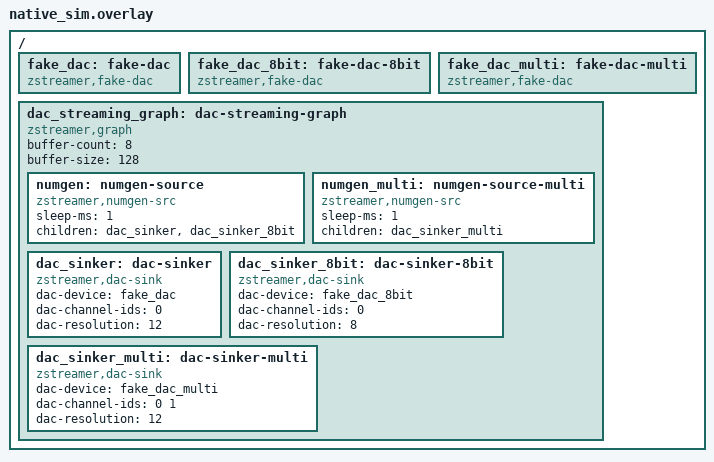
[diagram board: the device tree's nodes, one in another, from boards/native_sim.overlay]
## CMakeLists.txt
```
# Copyright (c) 2026 sharonthecreator
# SPDX-License-Identifier: Apache-2.0

cmake_minimum_required(VERSION 3.20.0)

# Pick up test-local DTS bindings (fake DAC).
list(APPEND DTS_ROOT ${CMAKE_CURRENT_SOURCE_DIR})

find_package(Zephyr REQUIRED HINTS $ENV{ZEPHYR_BASE})
project(zstreamer_dac_test)

target_sources(app PRIVATE
  src/main.c
  src/fake_dac.c
)
target_include_directories(app PRIVATE ${CMAKE_CURRENT_SOURCE_DIR}/../../include)
```

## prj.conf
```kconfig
# Copyright (c) 2026 sharonthecreator
# SPDX-License-Identifier: Apache-2.0

CONFIG_ZTEST=y
CONFIG_ZSTREAMER=y

# Sink under test
CONFIG_ZSTREAMER_DAC_SINK=y
CONFIG_DAC=y

# Test drivers
CONFIG_ZSTREAMER_TEST_NUMGEN_SRC=y

CONFIG_LOG=y
CONFIG_NET_BUF_POOL_USAGE=y
```

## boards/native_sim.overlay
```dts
/*
 * Copyright (c) 2026 sharonthecreator
 * SPDX-License-Identifier: Apache-2.0
 */

/ {
	fake_dac: fake-dac {
		compatible = "zstreamer,fake-dac";
		status = "okay";
	};

	fake_dac_8bit: fake-dac-8bit {
		compatible = "zstreamer,fake-dac";
		status = "okay";
	};

	fake_dac_multi: fake-dac-multi {
		compatible = "zstreamer,fake-dac";
		status = "okay";
	};

	dac_streaming_graph: dac-streaming-graph {
		compatible = "zstreamer,graph";
		buffer-count = <8>;
		buffer-size = <128>;

		numgen: numgen-source {
			compatible = "zstreamer,numgen-src";
			sleep-ms = <1>;
			children = <&dac_sinker>, <&dac_sinker_8bit>;
		};

		numgen_multi: numgen-source-multi {
			compatible = "zstreamer,numgen-src";
			sleep-ms = <1>;
			children = <&dac_sinker_multi>;
		};

		/* 12-bit sink, single channel */
		dac_sinker: dac-sinker {
			compatible = "zstreamer,dac-sink";
			dac-device = <&fake_dac>;
			dac-channel-ids = <0>;
			dac-resolution = <12>;
		};

		/* 8-bit sink, single channel */
		dac_sinker_8bit: dac-sinker-8bit {
			compatible = "zstreamer,dac-sink";
			dac-device = <&fake_dac_8bit>;
			dac-channel-ids = <0>;
			dac-resolution = <8>;
		};

		/* 12-bit sink, two channels (stereo) */
		dac_sinker_multi: dac-sinker-multi {
			compatible = "zstreamer,dac-sink";
			dac-device = <&fake_dac_multi>;
			dac-channel-ids = <0 1>;
			dac-resolution = <12>;
		};
	};
};
```

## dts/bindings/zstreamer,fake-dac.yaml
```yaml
# Copyright (c) 2026 sharonthecreator
# SPDX-License-Identifier: Apache-2.0

description: Fake DAC for testing the dac_sink driver.

compatible: "zstreamer,fake-dac"
```

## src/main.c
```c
/*
 * Copyright (c) 2026 sharonthecreator
 * SPDX-License-Identifier: Apache-2.0
 *
 * DAC sink zstreamer node driver tests.
 *
 * Pipeline: numgen-src → dac-sinker (12-bit) + dac-sinker-8bit (8-bit)
 * Both sinks receive every buffer from numgen; each writes to its own
 * fake DAC so recordings don't interleave.
 *
 * Multi-channel pipeline: numgen-multi → dac-sinker-multi (2ch, 12-bit)
 */

#include <string.h>

#include <zephyr/device.h>
#include <zephyr/net_buf.h>
#include <zephyr/ztest.h>

#include <zstreamer/node.h>
#include <zstreamer/source.h>
#include <zstreamer_test/helpers.h>

#include "fake_dac.h"

/* ------------------------------------------------------------------ */
/* DTS nodes                                                           */
/* ------------------------------------------------------------------ */

#define GRAPH_NODE          DT_NODELABEL(dac_streaming_graph)
#define NUMGEN_NODE         DT_NODELABEL(numgen)
#define NUMGEN_MULTI_NODE   DT_NODELABEL(numgen_multi)
#define DAC_SINK_NODE       DT_NODELABEL(dac_sinker)
#define DAC_SINK_8BIT_NODE  DT_NODELABEL(dac_sinker_8bit)
#define DAC_SINK_MULTI_NODE DT_NODELABEL(dac_sinker_multi)
#define FAKE_DAC_NODE       DT_NODELABEL(fake_dac)
#define FAKE_DAC_8BIT_NODE  DT_NODELABEL(fake_dac_8bit)
#define FAKE_DAC_MULTI_NODE DT_NODELABEL(fake_dac_multi)

static const struct device *graph_dev = DEVICE_DT_GET(GRAPH_NODE);
static const struct device *numgen_dev = DEVICE_DT_GET(NUMGEN_NODE);
static const struct device *numgen_multi_dev = DEVICE_DT_GET(NUMGEN_MULTI_NODE);
static const struct device *dac_sink_dev = DEVICE_DT_GET(DAC_SINK_NODE);
static const struct device *dac_sink_8bit_dev = DEVICE_DT_GET(DAC_SINK_8BIT_NODE);
static const struct device *dac_sink_multi_dev = DEVICE_DT_GET(DAC_SINK_MULTI_NODE);
static const struct device *fake_dac_dev = DEVICE_DT_GET(FAKE_DAC_NODE);
static const struct device *fake_dac_8bit_dev = DEVICE_DT_GET(FAKE_DAC_8BIT_NODE);
static const struct device *fake_dac_multi_dev = DEVICE_DT_GET(FAKE_DAC_MULTI_NODE);

/* ------------------------------------------------------------------ */
/* Fixture                                                             */
/* ------------------------------------------------------------------ */

static void cleanup(void *fixture)
{
	ARG_UNUSED(fixture);

	zstreamer_source_stop(numgen_dev);
	zstreamer_source_stop(numgen_multi_dev);
	k_msleep(50);
	fake_dac_reset(fake_dac_dev);
	fake_dac_reset(fake_dac_8bit_dev);
	fake_dac_reset(fake_dac_multi_dev);
}

ZTEST_SUITE(zstreamer_dac, NULL, NULL, cleanup, cleanup, NULL);

/* ------------------------------------------------------------------ */
/* Basic tests                                                         */
/* ------------------------------------------------------------------ */

ZTEST(zstreamer_dac, test_devices_ready)
{
	zassert_true(device_is_ready(graph_dev), "graph not ready");
	zassert_true(device_is_ready(numgen_dev), "numgen not ready");
	zassert_true(device_is_ready(numgen_multi_dev), "numgen_multi not ready");
	zassert_true(device_is_ready(dac_sink_dev), "dac_sink not ready");
	zassert_true(device_is_ready(dac_sink_8bit_dev), "dac_sink_8bit not ready");
	zassert_true(device_is_ready(dac_sink_multi_dev), "dac_sink_multi not ready");
	zassert_true(device_is_ready(fake_dac_dev), "fake_dac not ready");
	zassert_true(device_is_ready(fake_dac_8bit_dev), "fake_dac_8bit not ready");
	zassert_true(device_is_ready(fake_dac_multi_dev), "fake_dac_multi not ready");
}

ZTEST(zstreamer_dac, test_start_stop)
{
	int ret;

	ret = zstreamer_source_start(numgen_dev);
	zassert_equal(ret, 0, "start failed: %d", ret);

	ret = zstreamer_source_start(numgen_dev);
	zassert_equal(ret, -EALREADY, "double start: %d", ret);

	ret = zstreamer_source_stop(numgen_dev);
	zassert_equal(ret, 0, "stop failed: %d", ret);

	ret = zstreamer_source_stop(numgen_dev);
	zassert_equal(ret, -EALREADY, "double stop: %d", ret);
}

/* ------------------------------------------------------------------ */
/* 12-bit DAC output tests                                             */
/* ------------------------------------------------------------------ */

ZTEST(zstreamer_dac, test_16bit_dac_called)
{
	int ret;

	ret = zstreamer_source_start(numgen_dev);
	zassert_equal(ret, 0);

	k_msleep(200);

	ret = zstreamer_source_stop(numgen_dev);
	zassert_equal(ret, 0);

	k_msleep(50);

	zassert_true(fake_dac_get_write_count(fake_dac_dev) > 0,
		     "DAC write_value was never called");
}

ZTEST(zstreamer_dac, test_16bit_values_in_range)
{
	int ret;

	ret = zstreamer_source_start(numgen_dev);
	zassert_equal(ret, 0);

	k_msleep(200);

	ret = zstreamer_source_stop(numgen_dev);
	zassert_equal(ret, 0);

	k_msleep(50);

	uint32_t n = fake_dac_get_recorded_count(fake_dac_dev);

	zassert_true(n > 0, "no values recorded");

	for (uint32_t i = 0; i < n; i++) {
		uint32_t val = fake_dac_get_recorded_value(fake_dac_dev, i);

		zassert_true(val <= 4095, "sample %u: value %u out of 12-bit range", i, val);
	}
}

/**
 * Verify the 12-bit DAC output matches the numgen byte pattern.
 *
 * numgen fills buffers with incrementing bytes.  The 16-bit dac_sink
 * interprets consecutive byte-pairs as little-endian uint16_t and
 * masks to 12 bits.
 */
ZTEST(zstreamer_dac, test_16bit_data_integrity)
{
	int ret;

	ret = zstreamer_source_start(numgen_dev);
	zassert_equal(ret, 0);

	k_msleep(50);

	ret = zstreamer_source_stop(numgen_dev);
	zassert_equal(ret, 0);

	k_msleep(50);

	uint32_t n = fake_dac_get_recorded_count(fake_dac_dev);

	zassert_true(n >= 2, "need at least 2 DAC values, got %u", n);

	uint32_t first = fake_dac_get_recorded_value(fake_dac_dev, 0);
	uint32_t second = fake_dac_get_recorded_value(fake_dac_dev, 1);

	/* Derive byte offset from the first two samples. */
	int start = -1;

	for (int b = 0; b < 256; b += 2) {
		uint8_t lo0 = (uint8_t)(b & 0xFF);
		uint8_t hi0 = (uint8_t)((b + 1) & 0xFF);
		uint32_t exp0 = ((uint16_t)hi0 << 8 | lo0) & 0xFFF;

		uint8_t lo1 = (uint8_t)((b + 2) & 0xFF);
		uint8_t hi1 = (uint8_t)((b + 3) & 0xFF);
		uint32_t exp1 = ((uint16_t)hi1 << 8 | lo1) & 0xFFF;

		if (exp0 == first && exp1 == second) {
			start = b;
			break;
		}
	}

	zassert_true(start >= 0, "could not derive byte offset from first=%u second=%u", first,
		     second);

	for (uint32_t i = 0; i < n; i++) {
		uint32_t b = (start + 2 * i) & 0xFFFF;
		uint8_t lo = (uint8_t)(b & 0xFF);
		uint8_t hi = (uint8_t)((b + 1) & 0xFF);
		uint32_t expected = ((uint16_t)hi << 8 | lo) & 0xFFF;
		uint32_t actual = fake_dac_get_recorded_value(fake_dac_dev, i);

		zassert_equal(actual, expected, "sample %u: DAC %u != expected %u (lo=%u hi=%u)", i,
			      actual, expected, lo, hi);
	}
}

/* ------------------------------------------------------------------ */
/* 8-bit DAC output tests                                              */
/* ------------------------------------------------------------------ */

ZTEST(zstreamer_dac, test_8bit_dac_called)
{
	int ret;

	ret = zstreamer_source_start(numgen_dev);
	zassert_equal(ret, 0);

	k_msleep(200);

	ret = zstreamer_source_stop(numgen_dev);
	zassert_equal(ret, 0);

	k_msleep(50);

	zassert_true(fake_dac_get_write_count(fake_dac_8bit_dev) > 0,
		     "8-bit DAC write_value was never called");
}

ZTEST(zstreamer_dac, test_8bit_values_in_range)
{
	int ret;

	ret = zstreamer_source_start(numgen_dev);
	zassert_equal(ret, 0);

	k_msleep(200);

	ret = zstreamer_source_stop(numgen_dev);
	zassert_equal(ret, 0);

	k_msleep(50);

	uint32_t n = fake_dac_get_recorded_count(fake_dac_8bit_dev);

	zassert_true(n > 0, "no 8-bit values recorded");

	for (uint32_t i = 0; i < n; i++) {
		uint32_t val = fake_dac_get_recorded_value(fake_dac_8bit_dev, i);

		zassert_true(val <= 255, "sample %u: value %u out of 8-bit range", i, val);
	}
}

/**
 * Verify the 8-bit DAC output matches the numgen byte pattern.
 *
 * The 8-bit dac_sink reads one byte at a time from the buffer and
 * masks to 8 bits.  numgen produces incrementing bytes, so the DAC
 * values should be a contiguous ascending sequence (mod 256).
 */
ZTEST(zstreamer_dac, test_8bit_data_integrity)
{
	int ret;

	ret = zstreamer_source_start(numgen_dev);
	zassert_equal(ret, 0);

	k_msleep(50);

	ret = zstreamer_source_stop(numgen_dev);
	zassert_equal(ret, 0);

	k_msleep(50);

	uint32_t n = fake_dac_get_recorded_count(fake_dac_8bit_dev);

	zassert_true(n >= 2, "need at least 2 values, got %u", n);

	/* Derive starting byte from first value, verify sequence. */
	uint32_t first = fake_dac_get_recorded_value(fake_dac_8bit_dev, 0);

	for (uint32_t i = 0; i < n; i++) {
		uint32_t expected = (first + i) & 0xFF;
		uint32_t actual = fake_dac_get_recorded_value(fake_dac_8bit_dev, i);

		zassert_equal(actual, expected, "sample %u: DAC %u != expected %u", i, actual,
			      expected);
	}
}

ZTEST(zstreamer_dac, test_8bit_more_samples_than_16bit)
{
	int ret;

	ret = zstreamer_source_start(numgen_dev);
	zassert_equal(ret, 0);

	k_msleep(200);

	ret = zstreamer_source_stop(numgen_dev);
	zassert_equal(ret, 0);

	k_msleep(50);

	uint32_t w_16 = fake_dac_get_write_count(fake_dac_dev);
	uint32_t w_8 = fake_dac_get_write_count(fake_dac_8bit_dev);

	zassert_true(w_16 > 0, "12-bit: no samples");
	zassert_true(w_8 > 0, "8-bit: no samples");

	/*
	 * Both sinks receive the same buffers.  The 8-bit sink processes
	 * 1 byte per sample, the 16-bit sink processes 2 bytes per sample.
	 * So the 8-bit sink should produce ~2x more DAC writes.
	 */
	zassert_true(w_8 > w_16, "8-bit writes (%u) should exceed 16-bit writes (%u)", w_8, w_16);
}

/* ------------------------------------------------------------------ */
/* Multi-channel tests                                                 */
/* ------------------------------------------------------------------ */

ZTEST(zstreamer_dac, test_multi_channel_dac_called)
{
	int ret;

	ret = zstreamer_source_start(numgen_multi_dev);
	zassert_equal(ret, 0);

	k_msleep(200);

	ret = zstreamer_source_stop(numgen_multi_dev);
	zassert_equal(ret, 0);

	k_msleep(50);

	zassert_true(fake_dac_get_write_count(fake_dac_multi_dev) > 0,
		     "multi-channel DAC write_value was never called");
}

ZTEST(zstreamer_dac, test_multi_channel_alternates)
{
	int ret;

	ret = zstreamer_source_start(numgen_multi_dev);
	zassert_equal(ret, 0);

	k_msleep(100);

	ret = zstreamer_source_stop(numgen_multi_dev);
	zassert_equal(ret, 0);

	k_msleep(50);

	uint32_t n = fake_dac_get_recorded_count(fake_dac_multi_dev);

	zassert_true(n >= 4, "need at least 4 values for 2-ch test, got %u", n);

	/*
	 * With 2 channels, writes should alternate: ch0, ch1, ch0, ch1, ...
	 */
	for (uint32_t i = 0; i < n; i++) {
		uint8_t expected_ch = (i % 2 == 0) ? 0 : 1;
		uint8_t actual_ch = fake_dac_get_recorded_channel(fake_dac_multi_dev, i);

		zassert_equal(actual_ch, expected_ch, "write %u: channel %u != expected %u", i,
			      actual_ch, expected_ch);
	}
}

ZTEST(zstreamer_dac, test_multi_channel_values_in_range)
{
	int ret;

	ret = zstreamer_source_start(numgen_multi_dev);
	zassert_equal(ret, 0);

	k_msleep(200);

	ret = zstreamer_source_stop(numgen_multi_dev);
	zassert_equal(ret, 0);

	k_msleep(50);

	uint32_t n = fake_dac_get_recorded_count(fake_dac_multi_dev);

	zassert_true(n > 0, "no multi-channel values recorded");

	for (uint32_t i = 0; i < n; i++) {
		uint32_t val = fake_dac_get_recorded_value(fake_dac_multi_dev, i);

		zassert_true(val <= 4095, "sample %u: value %u out of 12-bit range", i, val);
	}
}

/* ------------------------------------------------------------------ */
/* Common tests                                                        */
/* ------------------------------------------------------------------ */

ZTEST(zstreamer_dac, test_multiple_buffers)
{
	int ret;

	ret = zstreamer_source_start(numgen_dev);
	zassert_equal(ret, 0);

	k_msleep(100);
	uint32_t mid = fake_dac_get_write_count(fake_dac_dev);

	k_msleep(100);

	ret = zstreamer_source_stop(numgen_dev);
	zassert_equal(ret, 0);

	k_msleep(50);

	uint32_t final_count = fake_dac_get_write_count(fake_dac_dev);

	zassert_true(mid > 0, "no writes at midpoint");
	zassert_true(final_count > mid, "no additional writes after midpoint");
}

ZTEST(zstreamer_dac, test_restart_cycle)
{
	int ret;

	for (int cycle = 0; cycle < 5; cycle++) {
		fake_dac_reset(fake_dac_dev);
		fake_dac_reset(fake_dac_8bit_dev);

		ret = zstreamer_source_start(numgen_dev);
		zassert_equal(ret, 0, "cycle %d start", cycle);

		k_msleep(100);

		ret = zstreamer_source_stop(numgen_dev);
		zassert_equal(ret, 0, "cycle %d stop", cycle);

		k_msleep(50);

		zassert_true(fake_dac_get_write_count(fake_dac_dev) > 0,
			     "cycle %d: no 12-bit DAC writes", cycle);
		zassert_true(fake_dac_get_write_count(fake_dac_8bit_dev) > 0,
			     "cycle %d: no 8-bit DAC writes", cycle);
	}
}

/* ------------------------------------------------------------------ */
/* Pool cleanup                                                        */
/* ------------------------------------------------------------------ */

ZTEST(zstreamer_dac, test_pool_free)
{
	int ret;

	ret = zstreamer_source_start(numgen_dev);
	zassert_equal(ret, 0);

	k_msleep(200);

	ret = zstreamer_source_stop(numgen_dev);
	zassert_equal(ret, 0);

	assert_pool_free(graph_dev);
}
```

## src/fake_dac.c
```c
/*
 * Copyright (c) 2026 sharonthecreator
 * SPDX-License-Identifier: Apache-2.0
 *
 * Minimal fake DAC driver for testing the dac_sink.
 * Records a history of written values for data integrity verification.
 */

#define DT_DRV_COMPAT zstreamer_fake_dac

#include <string.h>

#include <zephyr/device.h>
#include <zephyr/drivers/dac.h>
#include <zephyr/sys/atomic.h>

#include "fake_dac.h"

struct fake_dac_data {
  atomic_t write_count;
  uint32_t last_value;
  uint32_t recorded[FAKE_DAC_MAX_RECORDED];
  uint8_t recorded_ch[FAKE_DAC_MAX_RECORDED];
  uint32_t num_recorded;
};

static int fake_dac_channel_setup(const struct device *dev,
                                  const struct dac_channel_cfg *channel_cfg) {
  ARG_UNUSED(dev);
  ARG_UNUSED(channel_cfg);
  return 0;
}

static int fake_dac_write_value(const struct device *dev, uint8_t channel,
                                uint32_t value) {
  struct fake_dac_data *data = dev->data;

  data->last_value = value;

  if (data->num_recorded < FAKE_DAC_MAX_RECORDED) {
    data->recorded[data->num_recorded] = value;
    data->recorded_ch[data->num_recorded] = channel;
    data->num_recorded++;
  }

  atomic_inc(&data->write_count);

  return 0;
}

uint32_t fake_dac_get_write_count(const struct device *dev) {
  struct fake_dac_data *data = dev->data;
  return (uint32_t)atomic_get(&data->write_count);
}

uint32_t fake_dac_get_last_value(const struct device *dev) {
  struct fake_dac_data *data = dev->data;
  return data->last_value;
}

uint32_t fake_dac_get_recorded_count(const struct device *dev) {
  struct fake_dac_data *data = dev->data;
  return data->num_recorded;
}

uint32_t fake_dac_get_recorded_value(const struct device *dev, uint32_t idx) {
  struct fake_dac_data *data = dev->data;

  if (idx >= data->num_recorded) {
    return 0;
  }
  return data->recorded[idx];
}

uint8_t fake_dac_get_recorded_channel(const struct device *dev, uint32_t idx) {
  struct fake_dac_data *data = dev->data;

  if (idx >= data->num_recorded) {
    return 0xFF;
  }
  return data->recorded_ch[idx];
}

void fake_dac_reset(const struct device *dev) {
  struct fake_dac_data *data = dev->data;
  atomic_set(&data->write_count, 0);
  data->last_value = 0;
  data->num_recorded = 0;
  memset(data->recorded, 0, sizeof(data->recorded));
  memset(data->recorded_ch, 0, sizeof(data->recorded_ch));
}

static int fake_dac_init(const struct device *dev) {
  ARG_UNUSED(dev);
  return 0;
}

static DEVICE_API(dac, fake_dac_api) = {
    .channel_setup = fake_dac_channel_setup,
    .write_value = fake_dac_write_value,
};

#define FAKE_DAC_DEFINE(inst)                                                  \
  static struct fake_dac_data fake_dac_data_##inst;                            \
  DEVICE_DT_INST_DEFINE(inst, fake_dac_init, NULL, &fake_dac_data_##inst,      \
                        NULL, POST_KERNEL, CONFIG_KERNEL_INIT_PRIORITY_DEVICE, \
                        &fake_dac_api);

DT_INST_FOREACH_STATUS_OKAY(FAKE_DAC_DEFINE)
```

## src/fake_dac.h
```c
/*
 * Copyright (c) 2026 sharonthecreator
 * SPDX-License-Identifier: Apache-2.0
 */

#ifndef FAKE_DAC_H_
#define FAKE_DAC_H_

#include <stdint.h>
#include <zephyr/device.h>

#ifdef __cplusplus
extern "C" {
#endif

#define FAKE_DAC_MAX_RECORDED 512

uint32_t fake_dac_get_write_count(const struct device *dev);
uint32_t fake_dac_get_last_value(const struct device *dev);

/** Number of recorded values (capped at FAKE_DAC_MAX_RECORDED). */
uint32_t fake_dac_get_recorded_count(const struct device *dev);

/** Get the idx-th recorded value.  Returns 0 if idx is out of range. */
uint32_t fake_dac_get_recorded_value(const struct device *dev, uint32_t idx);

/** Get the channel of the idx-th recorded write.  Returns 0xFF if out of range.
 */
uint8_t fake_dac_get_recorded_channel(const struct device *dev, uint32_t idx);

void fake_dac_reset(const struct device *dev);

#ifdef __cplusplus
}
#endif

#endif /* FAKE_DAC_H_ */
```
